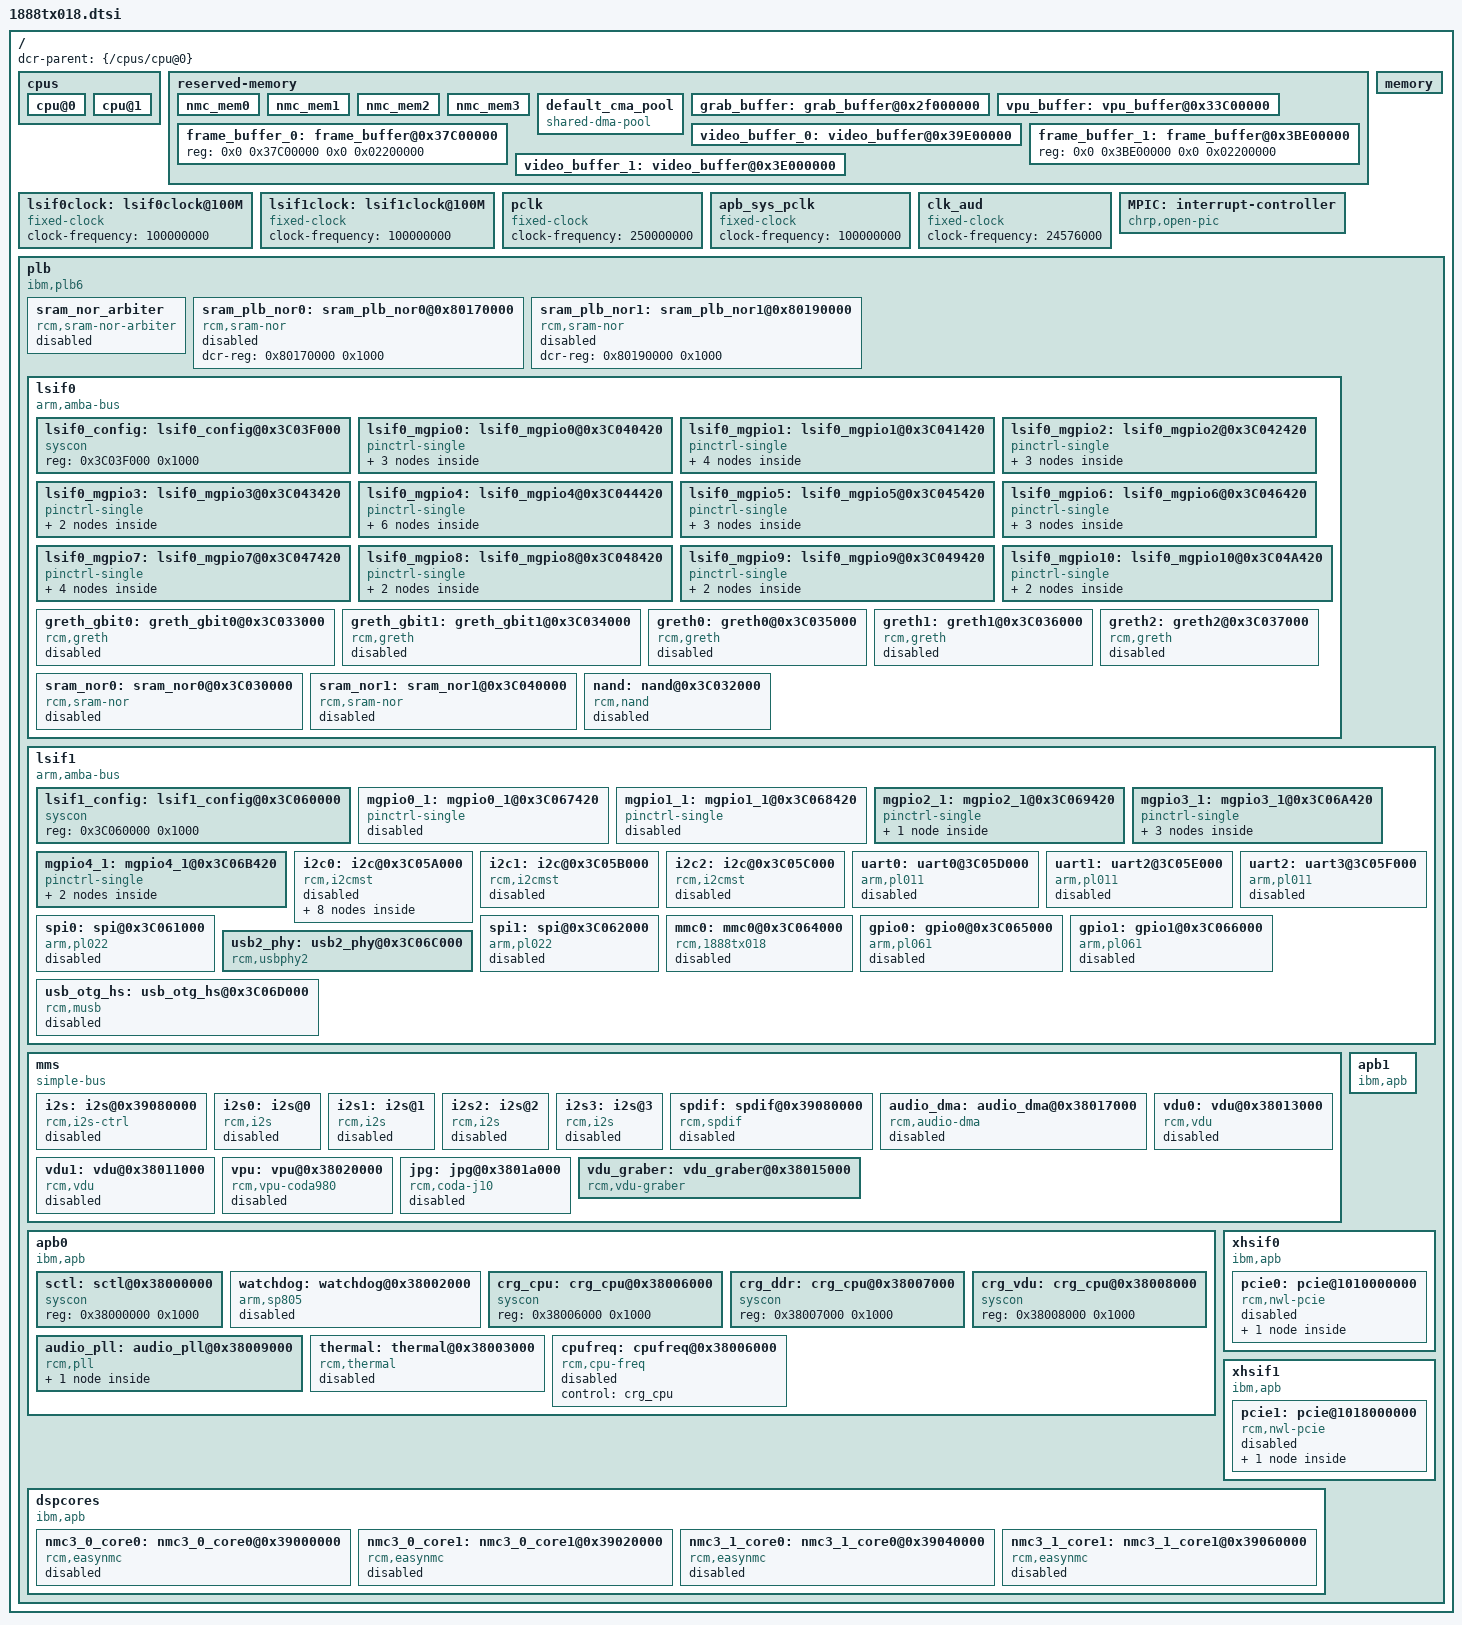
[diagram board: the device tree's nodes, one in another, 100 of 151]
/*
 * Device Tree Source for RCM 1888TX018 platform
 *
 * Copyright © 2019 Alexey Spirkov <dev@alsp.net>
 *
 * This file is licensed under the terms of the GNU General Public
 * License version 2.  This program is licensed "as is" without
 * any warranty of any kind, whether express or implied.
 */

/dts-v1/;

/ {
	#address-cells = <2>;
	#size-cells = <2>;
	dcr-parent = <&{/cpus/cpu@0}>;

	cpus {
		#address-cells = <1>;
		#size-cells = <0>;

		cpu@0 {
			status = "ok";
			device_type = "cpu";
			model = "PowerPC,470S";
			reg = <0>;
			clock-frequency = <800000000>; // 800 Mhz
			timebase-frequency = <800000000>; // 800Mhz
			i-cache-line-size = <32>;
			d-cache-line-size = <32>;
			i-cache-size = <32768>;
			d-cache-size = <32768>;
			dcr-controller;
			dcr-access-method = "native";
		};
		cpu@1 {
			status = "ok";
			device_type = "cpu";
			model = "PowerPC,470S";
			reg = <1>;
			clock-frequency = <80000000>; // 800 Mhz
			timebase-frequency = <800000000>; // 800Mhz
			i-cache-line-size = <32>;
			d-cache-line-size = <32>;
			i-cache-size = <32768>;
			d-cache-size = <32768>;
			dcr-controller;
			dcr-access-method = "native";
			enable-method = "spin-table";
			cpu-release-addr = <0x010 0x0007FFE0>;

		};
	};

	reserved-memory {
			#address-cells = <2>;
			#size-cells = <2>;
			ranges;

			nmc_mem0: nmc_mem0 {
					size = <0 0x1000000>;
					alignment = <0 0x1000000>;
			};
			nmc_mem1: nmc_mem1 {
					size = <0 0x1000000>;
					alignment = <0 0x1000000>;
			};
			nmc_mem2: nmc_mem2 {
					size = <0 0x1000000>;
					alignment = <0 0x1000000>;
			};
			nmc_mem3: nmc_mem3 {
					size = <0 0x1000000>;
					alignment = <0 0x1000000>;
			};

			default_cma_pool: default_cma_pool {
				compatible = "shared-dma-pool";
				reusable;
				alloc-ranges = <0x0 0x00000000 0x0 0x30000000>; // shall be in DMA zone
				size = <0x0 0x4000000>;
				alignment = <0x0 0x1000000>;
				linux,cma-default;
			};

			grab_buffer: grab_buffer@0x2f000000 {
				reg = <0x0 0x32000000 0x0 0x01C00000>;
				no-map;
			};

			vpu_buffer: vpu_buffer@0x33C00000 {
				reg = <0x0 0x33C00000 0x0 0x04000000>;
				no-map;
			};

			frame_buffer_0: frame_buffer@0x37C00000 {
				reg = <0x0 0x37C00000 0x0 0x02200000>;
			};
			video_buffer_0: video_buffer@0x39E00000 {
				no-map;
				reg = <0x0 0x39E00000 0x0 0x02000000>;
			};

			frame_buffer_1: frame_buffer@0x3BE00000 {
				reg = <0x0 0x3BE00000 0x0 0x02200000>;
			};
			video_buffer_1: video_buffer@0x3E000000 {
				no-map;
				reg = <0x0 0x3E000000 0x0 0x02000000>;
			};
	};

	memory {
		device_type = "memory";
		reg = <0x00000000 0x00000000 0x00000000 0x00000000>; // should be mofified at startup
	};

	lsif0clock: lsif0clock@100M {
		#clock-cells = <0>;
		compatible = "fixed-clock";
		clock-frequency = <100000000>;
	};

	lsif1clock: lsif1clock@100M {
		#clock-cells = <0>;
		compatible = "fixed-clock";
		clock-frequency = <100000000>;
	};

	pclk: pclk {
		#clock-cells = <0>;
		compatible = "fixed-clock";
		clock-frequency = <250000000>;
	};

	apb_sys_pclk: apb_sys_pclk {
		#clock-cells = <0>;
		compatible = "fixed-clock";
		clock-frequency = <100000000>;
	};

	clk_aud: clk_aud {
		#clock-cells = <0>;
		compatible = "fixed-clock";
		clock-frequency = <24576000>;
	};

	MPIC: interrupt-controller {
		compatible = "chrp,open-pic";
		interrupt-controller;
		dcr-reg = <0xffc00000 0x00040000>;
		#address-cells = <0>;
		#size-cells = <0>;
		#interrupt-cells = <2>;
	};

	plb {
		compatible = "ibm,plb6";
		#address-cells = <2>;
		#size-cells = <2>;
		ranges;
		dma-ranges;
		clock-frequency = <250000000>; // 250Mhz

		sram_nor_arbiter {
			status = "disabled";
			compatible = "rcm,sram-nor-arbiter";
			sctl = <&sctl>;
			control = <&lsif0_config>;
		};

		sram_plb_nor0: sram_plb_nor0@0x80170000 {
			status = "disabled";
			compatible = "rcm,sram-nor","simple-bus";
			#address-cells = <1>;
			#size-cells = <1>;
			dcr-reg = <0x80170000 0x1000>;
			ranges = <0x00000000 0x4 0x00000000 0x10000000>;
			// interrupt-parent = <&MPIC>;
			// interrupts = <104 0>; // IRQ_TYPE_EDGE_RISING
		};

		sram_plb_nor1: sram_plb_nor1@0x80190000 {
			status = "disabled";
			compatible = "rcm,sram-nor","simple-bus";
			#address-cells = <1>;
			#size-cells = <1>;
			dcr-reg = <0x80190000 0x1000>;
			ranges = <0x00000000 0x6 0x00000000 0x20000000>;
			// interrupt-parent = <&MPIC>;
			// interrupts = <104 0>; // IRQ_TYPE_EDGE_RISING
		};

		lsif0 {
			compatible = "arm,amba-bus", "ibm,plb6";
			#address-cells = <1>;
			#size-cells = <1>;

			ranges = <0x3c030000 0x10 0x3c030000 0x0001B000
			          0x20000000 0x10 0x20000000 0x10000000
			          0x30000000 0x10 0x30000000 0x08000000>;

			dma-ranges = <0x40000000 0x00000000 0x00000000 0x40000000>;

			lsif0_config: lsif0_config@0x3C03F000 {
				compatible = "syscon";
				reg = <0x3C03F000 0x1000>;
			};

			lsif0_mgpio0: lsif0_mgpio0@0x3C040420 {
				compatible = "pinctrl-single";
				reg = <0x3C040420 4>;
				pinctrl-single,register-width = <32>;
				pinctrl-single,function-mask = <0x1>;
				#address-cells = <1>;
				#size-cells = <0>;
				#pinctrl-cells = <2>;
				pinctrl-single,bit-per-mux;

				lsif0_mgpio0_greth_gbit0_ext: lsif0_mgpio0_greth_gbit0_ext {
					pinctrl-single,bits = <0 0xFF 0xFF>;
				};

				lsif0_mgpio0_greth1_ext: lsif0_mgpio0_greth1_ext {
					pinctrl-single,bits = <0 0x3A 0x3A>;
				};

				lsif0_mgpio0_sram_nor: lsif0_mgpio0_sram_nor {
					pinctrl-single,bits = <0 0xFF 0xFF>;
				};
			};

			lsif0_mgpio1: lsif0_mgpio1@0x3C041420 {
				compatible = "pinctrl-single";
				reg = <0x3C041420 4>;
				pinctrl-single,register-width = <32>;
				pinctrl-single,function-mask = <0x1>;
				#address-cells = <1>;
				#size-cells = <0>;
				#pinctrl-cells = <2>;
				pinctrl-single,bit-per-mux;

				lsif0_mgpio1_greth_gbit0_ext: lsif0_mgpio1_greth_gbit0_ext {
					pinctrl-single,bits = <0 0x0F 0x0F>;
				};

				lsif0_mgpio1_greth_gbit1_ext: lsif0_mgpio1_greth_gbit1_ext {
					pinctrl-single,bits = <0 0xF0 0xF0>;
				};

				lsif0_mgpio1_greth0_ext: lsif0_mgpio1_greth0_ext {
					pinctrl-single,bits = <0 0xA0 0xA0>;
				};

				lsif0_mgpio1_sram_nor: lsif0_mgpio1_sram_nor {
					pinctrl-single,bits = <0 0xFF 0xFF>;
				};
			};

			lsif0_mgpio2: lsif0_mgpio2@0x3C042420 {
				compatible = "pinctrl-single";
				reg = <0x3C042420 4>;
				pinctrl-single,register-width = <32>;
				pinctrl-single,function-mask = <0x1>;
				#address-cells = <1>;
				#size-cells = <0>;
				#pinctrl-cells = <2>;
				pinctrl-single,bit-per-mux;

				lsif0_mgpio2_greth_gbit1_ext: lsif0_mgpio2_greth_gbit1_ext {
					pinctrl-single,bits = <0 0xFF 0xFF>;
				};

				lsif0_mgpio2_greth0_ext: lsif0_mgpio2_greth0_ext {
					pinctrl-single,bits = <0 0x03 0x03>;
				};

				lsif0_mgpio2_sram_nor: lsif0_mgpio2_sram_nor {
					pinctrl-single,bits = <0 0xFF 0xFF>;
				};
			};

			lsif0_mgpio3: lsif0_mgpio3@0x3C043420 {
				compatible = "pinctrl-single";
				reg = <0x3C043420 4>;
				pinctrl-single,register-width = <32>;
				pinctrl-single,function-mask = <0x1>;
				#address-cells = <1>;
				#size-cells = <0>;
				#pinctrl-cells = <2>;
				pinctrl-single,bit-per-mux;

				lsif0_mgpio3_sram_nor: lsif0_mgpio3_sram_nor {
					pinctrl-single,bits = <0 0xFF 0xFF>;
				};

				lsif0_mgpio3_nand: lsif0_mgpio3_nand {		// d7..d0
					pinctrl-single,bits = <0 0xFF 0xFF>;
				};
			};

			lsif0_mgpio4: lsif0_mgpio4@0x3C044420 {
				compatible = "pinctrl-single";
				reg = <0x3C044420 4>;
				pinctrl-single,register-width = <32>;
				pinctrl-single,function-mask = <0x1>;
				#address-cells = <1>;
				#size-cells = <0>;
				#pinctrl-cells = <2>;
				pinctrl-single,bit-per-mux;

				lsif0_mgpio4_greth_gbit0_ext: lsif0_mgpio4_greth_gbit0_ext {
					pinctrl-single,bits = <0 0xE4 0xE4>;
				};

				lsif0_mgpio4_greth_gbit1_ext: lsif0_mgpio4_greth_gbit1_ext {
					pinctrl-single,bits = <0 0x08 0x08>;
				};

				lsif0_mgpio4_greth0_ext: lsif0_mgpio4_greth0_ext {
					pinctrl-single,bits = <0 0x08 0x08>;
				};

				lsif0_mgpio4_greth1_ext: lsif0_mgpio4_greth1_ext {
					pinctrl-single,bits = <0 0xC4 0xC4>;
				};

				lsif0_mgpio4_sram_nor: lsif0_mgpio4_sram_nor {
					pinctrl-single,bits = <0 0xFF 0xFF>;
				};

				lsif0_mgpio4_nand: lsif0_mgpio4_nand {		// ready2n,ready1n
					pinctrl-single,bits = <0 0x03 0x03>;
				};

			};

			lsif0_mgpio5: lsif0_mgpio5@0x3C045420 {
				compatible = "pinctrl-single";
				reg = <0x3C045420 4>;
				pinctrl-single,register-width = <32>;
				pinctrl-single,function-mask = <0x1>;
				#address-cells = <1>;
				#size-cells = <0>;
				#pinctrl-cells = <2>;
				pinctrl-single,bit-per-mux;

				lsif0_mgpio5_greth_gbit0_ext: lsif0_mgpio5_greth_gbit0_ext {
					pinctrl-single,bits = <0 0xFF 0xFF>;
				};

				lsif0_mgpio5_greth1_ext: lsif0_mgpio5_greth1_ext {
					pinctrl-single,bits = <0 0xC0 0xC0>;
				};

				lsif0_mgpio5_sram_nor: lsif0_mgpio5_sram_nor {
					pinctrl-single,bits = <0 0xFF 0xFF>;
				};
			};

			lsif0_mgpio6: lsif0_mgpio6@0x3C046420 {
				compatible = "pinctrl-single";
				reg = <0x3C046420 4>;
				pinctrl-single,register-width = <32>;
				pinctrl-single,function-mask = <0x1>;
				#address-cells = <1>;
				#size-cells = <0>;
				#pinctrl-cells = <2>;
				pinctrl-single,bit-per-mux;

				lsif0_mgpio6_greth_gbit1_ext: lsif0_mgpio6_greth_gbit1_ext {
					pinctrl-single,bits = <0 0xFE 0xFE>;
				};

				lsif0_mgpio6_greth0_ext: lsif0_mgpio6_greth0_ext {
					pinctrl-single,bits = <0 0x0C 0x0C>;
				};

				lsif0_mgpio6_sram_nor: lsif0_mgpio6_sram_nor {
					pinctrl-single,bits = <0 0xFF 0xFF>;
				};
			};

			lsif0_mgpio7: lsif0_mgpio7@0x3C047420 {
				compatible = "pinctrl-single";
				reg = <0x3C047420 4>;
				pinctrl-single,register-width = <32>;
				pinctrl-single,function-mask = <0x1>;
				#address-cells = <1>;
				#size-cells = <0>;
				#pinctrl-cells = <2>;
				pinctrl-single,bit-per-mux;

				lsif0_mgpio7_greth_gbit1_ext: lsif0_mgpio7_greth_gbit1_ext {
					pinctrl-single,bits = <0 0x0F 0x0F>;
				};

				lsif0_mgpio7_greth0_ext: lsif0_mgpio7_greth0_ext {
					pinctrl-single,bits = <0 0x0C 0x0C>;
				};

				lsif0_mgpio7_sram_nor: lsif0_mgpio7_sram_nor {
					pinctrl-single,bits = <0 0xFF 0xFF>;
				};

				lsif0_mgpio7_nand: lsif0_mgpio7_nand {		// ce1n, ce2n, cle, ren
					pinctrl-single,bits = <0 0xF0 0xF0>;
				};
			};

			lsif0_mgpio8: lsif0_mgpio8@0x3C048420 {
				compatible = "pinctrl-single";
				reg = <0x3C048420 4>;
				pinctrl-single,register-width = <32>;
				pinctrl-single,function-mask = <0x1>;
				#address-cells = <1>;
				#size-cells = <0>;
				#pinctrl-cells = <2>;
				pinctrl-single,bit-per-mux;

				lsif0_mgpio8_sram_nor: lsif0_mgpio8_sram_nor {
					pinctrl-single,bits = <0 0xFF 0xFF>;
				};

				lsif0_mgpio8_nand: lsif0_mgpio8_nand {
					pinctrl-single,bits = <0 0x83 0x83>;	// wpn, wen, ale
				};
			};

			lsif0_mgpio9: lsif0_mgpio9@0x3C049420 {
				compatible = "pinctrl-single";
				reg = <0x3C049420 4>;
				pinctrl-single,register-width = <32>;
				pinctrl-single,function-mask = <0x1>;
				#address-cells = <1>;
				#size-cells = <0>;
				#pinctrl-cells = <2>;
				pinctrl-single,bit-per-mux;

				lsif0_mgpio9_greth_gbit1_gmii: lsif0_mgpio9_greth_gbit1_gmii {
					pinctrl-single,bits = <0 0xFF 0xFF>;
				};

				lsif0_mgpio9_greth2_rmii: lsif0_mgpio9_greth2_rmii {
					pinctrl-single,bits = <0 0x4E 0x4E>;
				};
			};

			lsif0_mgpio10: lsif0_mgpio10@0x3C04A420 {
				compatible = "pinctrl-single";
				reg = <0x3C04A420 4>;
				pinctrl-single,register-width = <32>;
				pinctrl-single,function-mask = <0x1>;
				#address-cells = <1>;
				#size-cells = <0>;
				#pinctrl-cells = <2>;
				pinctrl-single,bit-per-mux;

				lsif0_mgpio10_greth_gbit1_gmii: lsif0_mgpio10_greth_gbit1_gmii {
					pinctrl-single,bits = <0 0xFF 0xFF>;
				};

				lsif0_mgpio10_greth2_rmii: lsif0_mgpio10_greth2_rmii {
					pinctrl-single,bits = <0 0xCD 0xCD>;
				};
			};

			// GRETH_GBIT0
			greth_gbit0: greth_gbit0@0x3C033000 {
				status = "disabled";
				compatible = "rcm,greth";
				reg = <0x3C033000 0x1000>;
				control = <&lsif0_config>;
				interrupt-parent = <&MPIC>;
				interrupts = <103 0>; // IRQ_TYPE_EDGE_RISING
			};

			// GRETH_GBIT1
			greth_gbit1: greth_gbit1@0x3C034000 {
				status = "disabled";
				compatible = "rcm,greth";
				reg = <0x3C034000 0x1000>;
				control = <&lsif0_config>;
				interrupt-parent = <&MPIC>;
				interrupts = <108 0>; // IRQ_TYPE_EDGE_RISING
			};

			// GRETH0
			greth0: greth0@0x3C035000 {
				status = "disabled";
				compatible = "rcm,greth";
				reg = <0x3C035000 0x1000>;
				control = <&lsif0_config>;
				interrupt-parent = <&MPIC>;
				interrupts = <103 0>; // IRQ_TYPE_EDGE_RISING
			};

			// GRETH1
			greth1: greth1@0x3C036000 {
				status = "disabled";
				compatible = "rcm,greth";
				reg = <0x3C036000 0x1000>;
				control = <&lsif0_config>;
				interrupt-parent = <&MPIC>;
				interrupts = <104 0>; // IRQ_TYPE_EDGE_RISING
			};

			// GRETH2
			greth2: greth2@0x3C037000 {
				status = "disabled";
				compatible = "rcm,greth";
				reg = <0x3C037000 0x1000>;
				control = <&lsif0_config>;
				interrupt-parent = <&MPIC>;
				interrupts = <108 0>; // IRQ_TYPE_EDGE_RISING
			};

			sram_nor0: sram_nor0@0x3C030000 {
				status = "disabled";
				compatible = "rcm,sram-nor","simple-bus";
				#address-cells = <1>;
				#size-cells = <1>;
				reg = <0x3C030000 0x1000>;
				ranges = <0x00000000 0x20000000 0x10000000>;
				cs-mode = <1>; // 0 - cs in address, 1 - cs in reg
				addr-size = <22>; // min 10 max 26 bit
				timings = <0x1f1f0808>;
				// interrupt-parent = <&MPIC>;
				// interrupts = <104 0>; // IRQ_TYPE_EDGE_RISING
			};

			sram_nor1: sram_nor1@0x3C040000 {
				status = "disabled";
				compatible = "rcm,sram-nor","simple-bus";
				#address-cells = <1>;
				#size-cells = <1>;
				reg = <0x3C040000 0x1000>;
				ranges = <0x00000000 0x30000000 0x08000000>;
				cs-mode = <1>;  // 0 - cs in address, 1 - cs in reg
				addr-size = <26>; // min 10 max 26 bit
				timings = <0x1f1f0808>;
				// interrupt-parent = <&MPIC>;
				// interrupts = <104 0>; // IRQ_TYPE_EDGE_RISING
			};

			nand: nand@0x3C032000 {
				status = "disabled";
				compatible = "rcm,nand";
				#address-cells = <1>;
				#size-cells = <1>;
				reg = <0x3C032000 0x1000>;
				ranges = <0x00000000 0x20000000 0x20000000>;

				clocks = <&lsif0clock>;
				config = <&lsif0_config>;
				interrupt-parent = <&MPIC>;
				interrupts = <109 0>; // 0=low-to-high edge,1=active-low level,2=active-high level,3=high-to-low edge
				pinctrl-0 =
					<&lsif0_mgpio3_nand>,
					<&lsif0_mgpio4_nand>,
					<&lsif0_mgpio7_nand>,
					<&lsif0_mgpio8_nand>;
			};
		};	// lsif0

		lsif1 {
			compatible = "arm,amba-bus", "ibm,plb6";
			#address-cells = <1>;
			#size-cells = <1>;

			ranges = <0x3c050000 // from
				  0x010 0x3c050000 // to
				  0x00020000>; // size

			dma-ranges = <0x40000000 0x00000000 0x00000000 0x40000000>;

			lsif1_config: lsif1_config@0x3C060000 {
				compatible = "syscon";
				reg = <0x3C060000 0x1000>;
			};

			mgpio0_1: mgpio0_1@0x3C067420 {
				status = "disabled";
				compatible = "pinctrl-single";
				reg = <0x3C067420 1>;
				pinctrl-single,register-width = <8>;
				pinctrl-single,function-mask = <0x1>;
				#address-cells = <1>;
				#size-cells = <0>;
				#pinctrl-cells = <2>;
				pinctrl-single,bit-per-mux;
			};

			mgpio1_1: mgpio1_1@0x3C068420 {
				status = "disabled";
				compatible = "pinctrl-single";
				reg = <0x3C068420 1>;
				pinctrl-single,register-width = <8>;
				pinctrl-single,function-mask = <0x1>;
				#address-cells = <1>;
				#size-cells = <0>;
				#pinctrl-cells = <2>;
				pinctrl-single,bit-per-mux;
			};

			mgpio2_1: mgpio2_1@0x3C069420 {
				status = "ok";
				compatible = "pinctrl-single";
				reg = <0x3C069420 1>;
				pinctrl-single,register-width = <8>;
				pinctrl-single,function-mask = <0x1>;
				#address-cells = <1>;
				#size-cells = <0>;
				#pinctrl-cells = <2>;
				pinctrl-single,bit-per-mux;

				uart0_mux: uart0_mux_pinmux {
					pinctrl-single,bits = <0 0xC0 0xC0>;
				};
			};

			mgpio3_1: mgpio3_1@0x3C06A420 {
				status = "ok";
				compatible = "pinctrl-single";
				reg = <0x3C06A420 1>;
				pinctrl-single,register-width = <8>;
				pinctrl-single,function-mask = <0x1>;
				#address-cells = <1>;
				#size-cells = <0>;
				#pinctrl-cells = <2>;
				pinctrl-single,bit-per-mux;

				uart1_mux: uart1_mux_pinmux {
					pinctrl-single,bits = <0 0x03 0x03>;
				};

				uart2_mux: uart2_mux_pinmux {
					pinctrl-single,bits = <0 0x0C 0x0C>;
				};

				spi0_mux: spi0_mux_pinmux {
					pinctrl-single,bits = <0 0x70 0x70>; // register == afsel, value, mask
				};
			};

			mgpio4_1: mgpio4_1@0x3C06B420 {
				status = "ok";
				compatible = "pinctrl-single";
				reg = <0x3C06B420 1>;
				pinctrl-single,register-width = <8>;
				pinctrl-single,function-mask = <0x1>;
				#address-cells = <1>;
				#size-cells = <0>;
				#pinctrl-cells = <2>;
				pinctrl-single,bit-per-mux;

				spi1_mux: spi1_mux_pinmux {
					pinctrl-single,bits = <0 0x07 0x07>;
				};

				sdio_mux: sdio_mux_pinmux {
					pinctrl-single,bits = <0 0xF8 0xF8>;
				};
			};


			i2c0: i2c@0x3C05A000 {
				status = "disabled";
				compatible = "rcm,i2cmst";
				#address-cells = <1>;
				#size-cells = <0>;
				reg = <0x3C05A000 0x1000>;
				clocks = <&lsif1clock>;
				reg-shift = <2>;
				reg-io-width = <4>;
				interrupt-parent = <&MPIC>;
				interrupts = <99 0>;	// IRQ_TYPE_EDGE_RISING

				// HDMI channel 0
				adv7513_0: adv7513@39 {
					status = "disabled";
					compatible = "rcm,adv7513";
					reg = <0x39>;
				};

				// HDMI channel 1
				adv7513_1: adv7513@3d {
					status = "disabled";
					compatible = "rcm,adv7513";
					reg = <0x3D>;
				};

				// HDMI graber, channel 0
				adv7611_0: adv7611@4c {
					default-input = <0>;
					sample-alsb = <1>;
					compatible = "adi,adv7611";
					reg = <0x4c>, <0x42>, <0x40>, <0x3e>, <0x38>, <0x3c>, <0x26>, <0x32>, <0x36>, <0x34>, <0x30>, <0x22>, <0x24>;
					reg-names = "main",  "avlink","cec","infoframe","esdp", "dpp", "afe", "rep", "edid", "hdmi", "test", "cp", "vdp";
				    #address-cells = <1>;
					#size-cells = <0>;
					port@0 {
						reg = <0>;
						hdmi: endpoint_0 {
							hsync-active=<1>;
							vsync-active=<1>;
							pclk-sample=<1>;
						};
					};
				};

				// HDMI graber, channel 1
				adv7611_1: adv7611@4d {
					default-input = <0>;
					compatible = "adi,adv7611";
					reg = <0x4d>, <0x43>, <0x41>, <0x3f>, <0x39>, <0x3d>, <0x27>, <0x33>, <0x37>, <0x35>, <0x31>, <0x23>, <0x25>;
					reg-names = "main",  "avlink","cec","infoframe","esdp", "dpp", "afe", "rep", "edid", "hdmi", "test", "cp", "vdp";
				    #address-cells = <1>;
					#size-cells = <0>;
					port@0 {
						reg = <0>;
						hdmi_1: endpoint_1 {
							hsync-active=<1>;
							vsync-active=<1>;
							pclk-sample=<1>;
						};
					};
				};
			};

			i2c1: i2c@0x3C05B000 {
				status = "disabled";
				compatible = "rcm,i2cmst";
				#address-cells = <1>;
				#size-cells = <0>;
				reg = <0x3C05B000 0x1000>;
				clocks = <&lsif1clock>;
				reg-shift = <2>;
				reg-io-width = <4>;
				interrupt-parent = <&MPIC>;
				interrupts = <74 0>; // IRQ_TYPE_EDGE_RISING
			};

			i2c2: i2c@0x3C05C000 {
				status = "disabled";
				compatible = "rcm,i2cmst";
				#address-cells = <1>;
				#size-cells = <0>;
				reg = <0x3C05C000 0x1000>;
				clocks = <&lsif1clock>;
				reg-shift = <2>;
				reg-io-width = <4>;
				interrupt-parent = <&MPIC>;
				interrupts = <66 0>; // IRQ_TYPE_EDGE_RISING
			};

			uart0: uart0@3C05D000 {
				status = "disabled";
				compatible = "arm,pl011", "arm,primecell";
				reg = <0x3C05D000 0x1000>;
				clocks = <&lsif1clock>, <&pclk>;
				clock-names = "uartclk", "apb_pclk";
				pinctrl-names = "default";
				pinctrl-0 = <&uart0_mux>;
				interrupt-parent = <&MPIC>;
				interrupts = <101 0>; // IRQ_TYPE_EDGE_RISING
			};

			uart1: uart2@3C05E000 {
				status = "disabled";
				compatible = "arm,pl011", "arm,primecell";
				reg = <0x3C05E000 0x1000>;
				clocks = <&lsif1clock>, <&pclk>;
				clock-names = "uartclk", "apb_pclk";
				pinctrl-names = "default";
				pinctrl-0 = <&uart1_mux>;
				interrupt-parent = <&MPIC>;
				interrupts = <102 0>; // IRQ_TYPE_EDGE_RISING
			};

			uart2: uart3@3C05F000 {
				status = "disabled";
				compatible = "arm,pl011", "arm,primecell";
				reg = <0x3C05F000 0x1000>;
				clocks = <&lsif1clock>, <&pclk>;
				clock-names = "uartclk", "apb_pclk";
				pinctrl-names = "default";
				pinctrl-0 = <&uart2_mux>;
				interrupt-parent = <&MPIC>;
				interrupts = <65 0>; // IRQ_TYPE_EDGE_RISING
			};

			spi0: spi@0x3C061000 {
				status = "disabled";
				compatible = "arm,pl022", "arm,primecell";
				reg = <0x3C061000 0x1000>;
				interrupts = <100 0>; // IRQ_TYPE_EDGE_RISING
				#address-cells = <1>;
				#size-cells = <0>;
				interrupt-parent = <&MPIC>;
				clocks = <&pclk>;
				clock-names = "apb_pclk";
				pinctrl-names = "default";
				pinctrl-0 = <&spi0_mux>;
				num-cs = <1>;
				cs-gpios = <&gpio1 2 0>;
			};

			spi1: spi@0x3C062000 {
				status = "disabled";
				compatible = "arm,pl022", "arm,primecell";
				reg = <0x3C062000 0x1000>;
				interrupts = <73 0>; // IRQ_TYPE_EDGE_RISING
				#address-cells = <1>;
				#size-cells = <0>;
				interrupt-parent = <&MPIC>;
				clocks = <&pclk>;
				clock-names = "apb_pclk";
				pinctrl-names = "default";
				pinctrl-0 = <&spi1_mux>;
				num-cs = <1>;
				cs-gpios = <&gpio1 3 0>;
			};

			mmc0: mmc0@0x3C064000 {
				status = "disabled";
				compatible = "rcm,1888tx018", "rcm,mmc-0.2";
				reg = <0x3C064000 0x1000>;
				interrupt-parent = <&MPIC>;
				interrupts = <67 0>; // IRQ_TYPE_EDGE_RISING
				pinctrl-names = "default";
				pinctrl-0 = <&sdio_mux>;
				clocks = <&lsif1clock>;
				min-frequency = <1000000>;
				max-frequency = <4000000>;
				clock-names = "mmc";
			};

			gpio0: gpio0@0x3C065000 {
				status = "disabled";
				#gpio-cells = <2>;
				compatible = "arm,pl061", "arm,primecell";
				gpio-controller;
				reg = <0x3C065000 0x1000>;
				interrupt-controller;
				#interrupt-cells = <2>;
				interrupt-parent = <&MPIC>;
				interrupts = <106 0>; // IRQ_TYPE_EDGE_RISING
				clocks = <&pclk>;
				clock-names = "apb_pclk";
			};

			gpio1: gpio1@0x3C066000 {
				status = "disabled";
				#gpio-cells = <2>;
				compatible = "arm,pl061", "arm,primecell";
				gpio-controller;
				reg = <0x3C066000 0x1000>;
				interrupt-controller;
				#interrupt-cells = <2>;
				interrupt-parent = <&MPIC>;
				interrupts = <107 0>; // IRQ_TYPE_EDGE_RISING
				clocks = <&pclk>;
				clock-names = "apb_pclk";
			};

			usb2_phy: usb2_phy@0x3C06C000
			{
				status = "ok";
				compatible = "rcm,usbphy2";
				reg = <0x3C06C000 0x1000>;
				control = <&lsif1_config>;
				#phy-cells = <0>;
			};

			usb_otg_hs: usb_otg_hs@0x3C06D000 {
				status = "disabled";
				compatible = "rcm,musb";
				reg = <0x3C06D000 0x7ff>;
				interrupt-parent = <&MPIC>;
				interrupts = <69 0>, <70 0>;
				interrupt-names = "mc", "dma";
				usb-phy = <&usb2_phy>;
				phys = <&usb2_phy>;
				phy-names = "usb2-phy";

				// select clock to 24mhz
				// set bit 10 - USBPHY_REFCLK_SEL
				control = <&sctl 8 10>; // control, reg, bit

				multipoint = <1>;
				num-eps = <16>;
				ram-bits = <12>;
				mode = <3>; // 1 - host, 2 - device, 3 - otg
				power = <250>;
			};
		};

		mms {
			compatible = "simple-bus";
			#address-cells = <1>;
			#size-cells = <1>;

			ranges = <0x38010000 0x010 0x38010000 0x00024000
				  0x39080000 0x010 0x39080000 0x00002000
				  0x33C00000 0x000 0x33C00000 0x0C400000>;

			dma-ranges = <0x40000000 0x000 0x00000000 0x40000000>;

			i2s: i2s@0x39080000 {
				status = "disabled";
				compatible = "rcm,i2s-ctrl";
				#i2s-cells = <1>;
				reg = <0x39080000 0x1000>;
				interrupt-parent = <&MPIC>;
				interrupts = <125 0>;
				clocks = <&audio_pll_div>;
				rcm,disable11025;
			};

			i2s0: i2s@0 {
				status = "disabled";
				compatible = "rcm,i2s";
				#sound-dai-cells = <0>;
				ctrl = <&i2s 0>;
				dmas = <&audio_dma 0>;
				dma-names = "rx";
			};

			i2s1: i2s@1 {
				status = "disabled";
				compatible = "rcm,i2s";
				#sound-dai-cells = <0>;
				ctrl = <&i2s 1>;
				dmas = <&audio_dma 1>;
				dma-names = "rx";
			};

			i2s2: i2s@2 {
				status = "disabled";
				compatible = "rcm,i2s";
				#sound-dai-cells = <0>;
				ctrl = <&i2s 2>;
				dmas = <&audio_dma 2>;
				dma-names = "rx";
			};

			i2s3: i2s@3 {
				status = "disabled";
				compatible = "rcm,i2s";
				#sound-dai-cells = <0>;
				ctrl = <&i2s 3>;
				dmas = <&audio_dma 3>;
				dma-names = "rx";
			};

			spdif: spdif@0x39080000 {
				status = "disabled";
				compatible = "rcm,spdif";
				#sound-dai-cells = <0>;
				reg = <0x39081000 0x1000>;
				interrupt-parent = <&MPIC>;
				interrupts = <126 0>;
				clocks = <&audio_pll_div>;
				dmas = <&audio_dma 4>;
				dma-names = "rx";
			};

			audio_dma: audio_dma@0x38017000 {
				status = "disabled";
				compatible = "rcm,audio-dma";
				reg = <0x38017000 0x1000>;
				#dma-cells = <1>;
				interrupt-parent = <&MPIC>;
				interrupts = <127 0>;
			};

			// HDMI channel 0 (actually VDU index 1)
			vdu0: vdu@0x38013000 {
				status = "disabled";
				compatible = "rcm,vdu";
				reg = <0x38013000 0x1000>;
				interrupt-parent = <&MPIC>;
				interrupts = <120 2>; // active high level-sensitive
				vdu-index = <1>;
				crg-control = <&crg_vdu>;
				supported_modes = <0x7FFE>;
				default_mode = <0x4>;
				output_flags = <0x200>;
				axi_osd_param = <0x0f310000>;
				axi_mvl_param = <0x0f310000>;
				memory-region = <&frame_buffer_1>;
				vdubuffer = <0x3E000000 0x02000000>;
			};

			// HDMI channel 1 (actually VDU index 0)
			vdu1: vdu@0x38011000 {
				status = "disabled";
				compatible = "rcm,vdu";
				reg = <0x38011000 0x1000>;
				interrupt-parent = <&MPIC>;
				interrupts = <117 2>; // active high level-sensitive
				vdu-index = <0>;
				crg-control = <&crg_vdu>;
				supported_modes = <0x7FFE>;
				default_mode = <0x4>;
				output_flags = <0x200>;
				axi_osd_param = <0x0f310000>;
				axi_mvl_param = <0x0f310000>;
				memory-region = <&frame_buffer_0>;
				vdubuffer = <0x39E00000 0x02000000>;
			};

			vpu: vpu@0x38020000 {
				status = "disabled";
				compatible = "rcm,vpu-coda980";
				reg = <0x38020000 0x4000>;
				interrupt-parent = <&MPIC>;
				interrupts = <123 2>; // active high level-sensitive
				memory-buffer = <&vpu_buffer>;
			};

			jpg: jpg@0x3801a000 {
				status = "disabled";
				compatible = "rcm,coda-j10";
				reg = <0x3801a000 0x1000>;
				interrupt-parent = <&MPIC>;
				interrupts = <124 2>; // active high level-sensitive
			};

		vdu_graber: vdu_graber@0x38015000 {
				compatible = "rcm,vdu-graber";
				reg = <0x38015000 0x1000>;					// INT0-15,EXT0-16,INT1-1b,EXT1-1c
				interrupt-parent = <&MPIC>;
				interrupts = <118 2>;						// INT0-18,EXT0-19,INT1-21,EXT1-22
				#address-cells = <1>;
				#size-cells = <1>;
				memory-region = <&grab_buffer>;	
			};
		};

		apb0 {
			compatible = "ibm,apb";
			#address-cells = <1>;
			#size-cells = <1>;

			ranges = <0x38000000 0x010 0x38000000 0x00010000>;

			sctl: sctl@0x38000000
			{
				compatible = "syscon";
				reg = <0x38000000 0x1000>;
			};

			watchdog: watchdog@0x38002000 {
				status = "disabled";
				compatible = "arm,sp805", "arm,primecell";
				reg = <0x38002000 0x1000>;
				interrupt-parent = <&MPIC>;
				interrupts = <36 0>; /* IRQ_TYPE_EDGE_RISING watchdog timer IRQ */
				clocks = <&apb_sys_pclk>,<&apb_sys_pclk>;
				clock-names = "wdogclk", "apb_pclk";
			};

			crg_cpu: crg_cpu@0x38006000
			{
				compatible = "syscon";
				reg = <0x38006000 0x1000>;
			};

			crg_ddr: crg_cpu@0x38007000
			{
				compatible = "syscon";
				reg = <0x38007000 0x1000>;
			};

			crg_vdu: crg_cpu@0x38008000
			{
				compatible = "syscon";
				reg = <0x38008000 0x1000>;
			};

			audio_pll: audio_pll@0x38009000
			{
				status ="ok";
				compatible = "rcm,pll", "simple-bus";
				#clock-cells = <0>;
				#address-cells = <1>;
				#size-cells = <0>;
				reg = <0x38009000 0x1000>;
				clocks = <&clk_aud>;
				//      fbdif  prdiv  psdiv
				freqs = <64      1      2>, // 393 216 000 Hz / 16 = 24 576 000
				        <147     1      2>; // 451 584 000 Hz / 20 = 22 579 200

				audio_pll_div: audio_pll_div@100
				{
					status ="ok";
					compatible = "rcm,pll-div";
					#clock-cells = <0>;
					reg = <0x100>;
					clocks = <&audio_pll>;
				};
			};

			thermal: thermal@0x38003000 {
				status = "disabled";
				compatible = "rcm,thermal";
				reg = <0x38003000 0x1000>;
				#thermal-sensor-cells = <0>;
				interrupt-parent = <&MPIC>;
				interrupts = <32 0 // IRQ_TYPE_EDGE_RISING temperature IRQ
				              33 0>; // IRQ_TYPE_EDGE_RISING  voltage IRQ
			};

			cpufreq: cpufreq@0x38006000 {
				status = "disabled";
				compatible = "rcm,cpu-freq";
				control = <&crg_cpu>;
			};
		};

		apb1 {
			compatible = "ibm,apb";
			#address-cells = <1>;
			#size-cells = <1>;
			ranges = <0x38010000 0x010 0x38010000 0x00010000>;
		};

		xhsif0 {
			compatible = "ibm,apb";	 // to check bus type
			#address-cells = <2>;
			#size-cells = <2>;
			ranges;

			pcie0: pcie@1010000000 {
				status = "disabled";
				compatible = "rcm,nwl-pcie";
				#address-cells = <3>;
				#size-cells = <2>;
				#interrupt-cells = <1>;
				msi-controller;
				device_type = "pci";
				interrupt-parent = <&MPIC>;
				interrupts = <86 4>, // misc
				             <87 4>, // DMA
				             <85 4>, // legacy
				             <84 4>, // MSI_1 [63...32]
				             <83 4>; // MSI_0 [31...0]
				interrupt-names =
					"misc", "dma", "legacy", "msi1", "msi0";
				msi-parent = <&pcie0>;
				reg = <0x010 0x10000000 0x0 0x1000000>, // PCI0
				      <0x10 0x3c000000 0x0 0x10000>, // xhsif0 pci control
				      <0x10 0x11000000 0x0 0x1000000>, // ecam
				      <0x10 0x3cb00000 0x0 0x40000>; // serdes
				reg-names = "breg", "pcireg", "cfg", "serdes";

				//        pci_space  < pci_addr          > < cpu_addr          > < size       >
				ranges = <0x03000000 0x00000000 0x12020000 0x00000010 0x12020000 0x0 0x05FE0000
				          0x03000000 0x00000003 0x00000000 0x00000012 0x00000000 0x1 0x00000000>;
				dma-ranges = <0x43000000 0x0 0x0 0x1 0x00000000 0x1 0x0
				              0x43000000 0x2 0x0 0x2 0x00000000 0x1 0x0>;

				bus-range = <0x00 0x0f>;
				interrupt-map-mask = <0x0 0x0 0x0 0x7>;
				interrupt-map = <0x0 0x0 0x0 0x1 &pcie0_intc 0x1>,
				                <0x0 0x0 0x0 0x2 &pcie0_intc 0x2>,
				                <0x0 0x0 0x0 0x3 &pcie0_intc 0x3>,
				                <0x0 0x0 0x0 0x4 &pcie0_intc 0x4>;
				pcie0_intc: legacy-interrupt-controller {
					interrupt-controller;
					#address-cells = <0>;
					#interrupt-cells = <1>;
				};
			};
		};

		xhsif1 {
			compatible = "ibm,apb";	 /* to check bus type */
			#address-cells = <2>;
			#size-cells = <2>;
			ranges;

			pcie1: pcie@1018000000 {
				status = "disabled";
				compatible = "rcm,nwl-pcie";
				#address-cells = <3>;
				#size-cells = <2>;
				#interrupt-cells = <1>;
				msi-controller;
				device_type = "pci";
				interrupt-parent = <&MPIC>;
				interrupts = <94 4>, // misc
				             <95 4>, // DMA
				             <93 4>, // legacy
				             <92 4>, // MSI_1 [63...32]
				             <91 4>; // MSI_0 [31...0]
				interrupt-names = "misc", "dma", "legacy",
						"msi1", "msi0";
				msi-parent = <&pcie1>;
				reg = <0x010 0x18000000 0x0 0x1000000>, // PCI0
				       <0x10 0x3c010000 0x0 0x10000>, // xhsif1 pci control
				       <0x10 0x19000000 0x0 0x1000000>, // ecam
				       <0x10 0x3cb40000 0x0 0x40000>; // serdes
				reg-names = "breg", "pcireg", "cfg", "serdes";

						  // https://elinux.org/Device_Tree_Usage#PCI_Host_Bridge
				//        pci_space  < pci_addr          > < cpu_addr          > < size       >
				ranges = <0x03000000 0x00000000 0x1a020000 0x00000010 0x1a020000 0x0 0x05FE0000
				          0x03000000 0x00000004 0x00000000 0x00000013 0x00000000 0x1 0x00000000>;
				dma-ranges = <0x43000000 0x0 0x0 0x1 0x00000000 0x1 0x0
				              0x43000000 0x2 0x0 0x2 0x00000000 0x1 0x0>;

				bus-range = <0x00 0x0f>;
				interrupt-map-mask = <0x0 0x0 0x0 0x7>;
				interrupt-map = <0x0 0x0 0x0 0x1 &pcie1_intc 0x1>,
				                <0x0 0x0 0x0 0x2 &pcie1_intc 0x2>,
				                <0x0 0x0 0x0 0x3 &pcie1_intc 0x3>,
				                <0x0 0x0 0x0 0x4 &pcie1_intc 0x4>;
				pcie1_intc: legacy-interrupt-controller {
					interrupt-controller;
					#address-cells = <0>;
					#interrupt-cells = <1>;
				};
			};
		};

		dspcores {
			compatible = "ibm,apb"; // to check bus type
			#address-cells = <1>;
			#size-cells = <1>;
			ranges = <0x39000000 0x010 0x39000000 0x000080000>;

			nmc3_0_core0: nmc3_0_core0@0x39000000 {
				status = "disabled";
				compatible = "rcm,easynmc";
				core-name = "K1879-nmc";
				core-type = "nmc3";
				device-id = <0>;

				reg = <0x39000000 0x00020000>; // imem
				reg-names = "imem";

				memory-region = <&nmc_mem0>;

				control = <&sctl>;
				reset = <&crg_cpu>;

				reset_bit =     <5>; // reset bit no
				lp_status_reg = <0x240>, <0>; // sctl offset, bit-no
				hp_status_reg = <0x240>, <1>; // sctl offset, bit-no
				lp_set_reg =    <0x248>, <0>; // sctl offset, bit-no
				hp_set_reg =    <0x248>, <1>; // sctl offset, bit-no
				nmi_set_reg =   <0x248>, <2>; // sctl offset, bit-no
				hp_clr_reg =    <0x244>, <0>; // sctl offset, bit-no
				lp_clr_reg =    <0x244>, <1>; // sctl offset, bit-no

				interrupt-parent = <&MPIC>;
				interrupts = <39 0>, <41 0>;
				interrupt-names = "lp", "hp";
			};
			nmc3_0_core1: nmc3_0_core1@0x39020000 {
				status = "disabled";
				compatible = "rcm,easynmc";
				core-name = "K1879-nmc";
				core-type = "nmc3";
				device-id = <1>;
				reg = <0x39020000 0x00020000>;	// imem
				reg-names = "imem";

				memory-region = <&nmc_mem1>;

				control = <&sctl>;
				reset = <&crg_cpu>;

				reset_bit =     <6>; // reset bit no
				lp_status_reg = <0x240>, <2>; // sctl offset, bit-no
				hp_status_reg = <0x240>, <3>; // sctl offset, bit-no
				lp_set_reg =    <0x248>, <3>; // sctl offset, bit-no
				hp_set_reg =    <0x248>, <4>; // sctl offset, bit-no
				nmi_set_reg =   <0x248>, <5>; // sctl offset, bit-no
				hp_clr_reg =    <0x244>, <2>; // sctl offset, bit-no
				lp_clr_reg =    <0x244>, <3>; // sctl offset, bit-no
				interrupt-parent = <&MPIC>;
				interrupts = <40 0>, <42 0>;
				interrupt-names = "lp", "hp";
			};
			nmc3_1_core0: nmc3_1_core0@0x39040000 {
				status = "disabled";
				compatible = "rcm,easynmc";
				core-name = "K1879-nmc";
				core-type = "nmc3";
				device-id = <2>;
				reg = <0x39040000 0x00020000>;	// imem
				reg-names = "imem";

				memory-region = <&nmc_mem2>;

				control = <&sctl>;
				reset = <&crg_cpu>;

				reset_bit =     <7>; // reset bit no
				lp_status_reg = <0x240>, <4>; // sctl offset, bit-no
				hp_status_reg = <0x240>, <5>; // sctl offset, bit-no
				lp_set_reg =    <0x248>, <6>; // sctl offset, bit-no
				hp_set_reg =    <0x248>, <7>; // sctl offset, bit-no
				nmi_set_reg =   <0x248>, <8>; // sctl offset, bit-no
				hp_clr_reg =    <0x244>, <4>; // sctl offset, bit-no
				lp_clr_reg =    <0x244>, <5>; // sctl offset, bit-no
				interrupt-parent = <&MPIC>;
				interrupts = <43 0>, <45 0>;
				interrupt-names = "lp", "hp";
			};
			nmc3_1_core1: nmc3_1_core1@0x39060000 {
				status = "disabled";
				compatible = "rcm,easynmc";
				core-name = "K1879-nmc";
				core-type = "nmc3";
				device-id = <3>;
				reg = <0x39060000 0x00020000>;	// imem
				reg-names = "imem";

				memory-region = <&nmc_mem3>;

				control = <&sctl>;
				reset = <&crg_cpu>;

				reset_bit =     <8>; // reset bit no
				lp_status_reg = <0x240>, <6>;  // sctl offset, bit-no
				hp_status_reg = <0x240>, <7>;  // sctl offset, bit-no
				lp_set_reg =    <0x248>, <9>;  // sctl offset, bit-no
				hp_set_reg =    <0x248>, <10>; // sctl offset, bit-no
				nmi_set_reg =   <0x248>, <11>; // sctl offset, bit-no
				hp_clr_reg =    <0x244>, <6>;  // sctl offset, bit-no
				lp_clr_reg =    <0x244>, <7>;  // sctl offset, bit-no
				interrupt-parent = <&MPIC>;
				interrupts = <44 0>, <46 0>;
				interrupt-names = "lp", "hp";
			};
		};
	};
};
